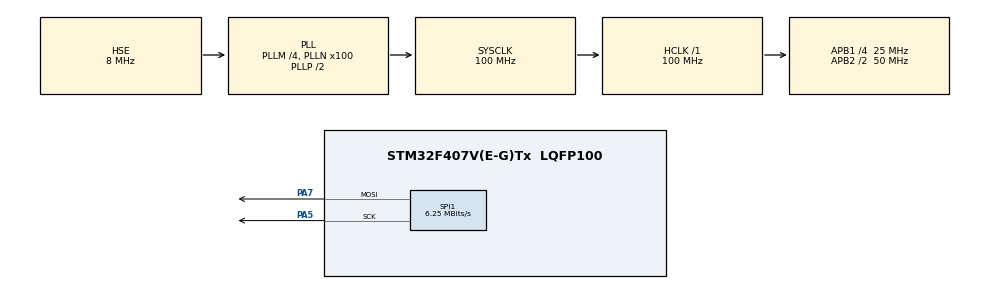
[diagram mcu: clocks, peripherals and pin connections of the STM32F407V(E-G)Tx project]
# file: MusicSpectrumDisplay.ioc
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Dma.Request0=SPI1_TX
Dma.SPI1_TX.0.Direction=DMA_MEMORY_TO_PERIPH
Dma.SPI1_TX.0.FIFOMode=DMA_FIFOMODE_DISABLE
Dma.SPI1_TX.0.Instance=DMA2_Stream3
Dma.SPI1_TX.0.MemDataAlignment=DMA_MDATAALIGN_BYTE
Dma.SPI1_TX.0.MemInc=DMA_MINC_ENABLE
Dma.SPI1_TX.0.Mode=DMA_CIRCULAR
Dma.SPI1_TX.0.PeriphDataAlignment=DMA_PDATAALIGN_BYTE
Dma.SPI1_TX.0.PeriphInc=DMA_PINC_DISABLE
Dma.SPI1_TX.0.Priority=DMA_PRIORITY_VERY_HIGH
Mcu.Family=STM32F4
Mcu.Name=STM32F407V(E-G)Tx
Mcu.Package=LQFP100
NVIC.DMA2_Stream3_IRQn=true\:0\:0\:false\:false\:true\:false
NVIC.PriorityGroup=NVIC_PRIORITYGROUP_4
PA5.Mode=TX_Only_Simplex_Unidirect_Master
PA5.Signal=SPI1_SCK
PA7.Mode=TX_Only_Simplex_Unidirect_Master
PA7.Signal=SPI1_MOSI
PH0-OSC_IN.Mode=HSE-External-Oscillator
PH0-OSC_IN.Signal=RCC_OSC_IN
PH1-OSC_OUT.Mode=HSE-External-Oscillator
PH1-OSC_OUT.Signal=RCC_OSC_OUT
ProjectManager.HeapSize=0x200
ProjectManager.StackSize=0x400
ProjectManager.TargetToolchain=SW4STM32
RCC.48MHZClocksFreq_Value=50000000
RCC.AHBFreq_Value=100000000
RCC.APB1CLKDivider=RCC_HCLK_DIV4
RCC.APB1Freq_Value=25000000
RCC.APB1TimFreq_Value=50000000
RCC.APB2CLKDivider=RCC_HCLK_DIV2
RCC.APB2Freq_Value=50000000
RCC.APB2TimFreq_Value=100000000
RCC.CortexFreq_Value=100000000
RCC.HCLKFreq_Value=100000000
RCC.HSE_VALUE=8000000
RCC.HSI_VALUE=16000000
RCC.LSE_VALUE=32768
RCC.PLLM=4
RCC.PLLN=100
RCC.PLLSourceVirtual=RCC_PLLSOURCE_HSE
RCC.SYSCLKFreq_VALUE=100000000
RCC.SYSCLKSource=RCC_SYSCLKSOURCE_PLLCLK
RCC.VCOOutputFreq_Value=200000000
SPI1.BaudRatePrescaler=SPI_BAUDRATEPRESCALER_8
SPI1.CalculateBaudRate=6.25 MBits/s
SPI1.Direction=SPI_DIRECTION_2LINES
SPI1.Mode=SPI_MODE_MASTER
SPI1.VirtualType=VM_MASTER
board=custom

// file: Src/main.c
/* USER CODE BEGIN Header */
/**
  ******************************************************************************
  * @file           : main.c
  * @brief          : Main program body
  ******************************************************************************
  ** This notice applies to any and all portions of this file
  * that are not between comment pairs USER CODE BEGIN and
  * USER CODE END. Other portions of this file, whether
  * inserted by the user or by software development tools
  * are owned by their respective copyright owners.
  *
  * COPYRIGHT(c) 2019 STMicroelectronics
  *
  * Redistribution and use in source and binary forms, with or without modification,
  * are permitted provided that the following conditions are met:
  *   1. Redistributions of source code must retain the above copyright notice,
  *      this list of conditions and the following disclaimer.
  *   2. Redistributions in binary form must reproduce the above copyright notice,
  *      this list of conditions and the following disclaimer in the documentation
  *      and/or other materials provided with the distribution.
  *   3. Neither the name of STMicroelectronics nor the names of its contributors
  *      may be used to endorse or promote products derived from this software
  *      without specific prior written permission.
  *
  * THIS SOFTWARE IS PROVIDED BY THE COPYRIGHT HOLDERS AND CONTRIBUTORS "AS IS"
  * AND ANY EXPRESS OR IMPLIED WARRANTIES, INCLUDING, BUT NOT LIMITED TO, THE
  * IMPLIED WARRANTIES OF MERCHANTABILITY AND FITNESS FOR A PARTICULAR PURPOSE ARE
  * DISCLAIMED. IN NO EVENT SHALL THE COPYRIGHT HOLDER OR CONTRIBUTORS BE LIABLE
  * FOR ANY DIRECT, INDIRECT, INCIDENTAL, SPECIAL, EXEMPLARY, OR CONSEQUENTIAL
  * DAMAGES (INCLUDING, BUT NOT LIMITED TO, PROCUREMENT OF SUBSTITUTE GOODS OR
  * SERVICES; LOSS OF USE, DATA, OR PROFITS; OR BUSINESS INTERRUPTION) HOWEVER
  * CAUSED AND ON ANY THEORY OF LIABILITY, WHETHER IN CONTRACT, STRICT LIABILITY,
  * OR TORT (INCLUDING NEGLIGENCE OR OTHERWISE) ARISING IN ANY WAY OUT OF THE USE
  * OF THIS SOFTWARE, EVEN IF ADVISED OF THE POSSIBILITY OF SUCH DAMAGE.
  *
  ******************************************************************************
  */
/* USER CODE END Header */

#include "main.h"

/* USER CODE BEGIN Includes */
#include "stm32f4xx_hal.h"
#include <stdlib.h>
#include <math.h>
#include "ws2812b.h"
#include "ws2812b_fx.h"
#include "msd_effect.h"
/* USER CODE END Includes */

SPI_HandleTypeDef hspi1;
DMA_HandleTypeDef hdma_spi1_tx;

/* USER CODE BEGIN PV */
uint16_t speedALL = 10000;
volatile int tablica_max_mocy[5]={6,8,12,8,6};
volatile int tablica_mocy[5]={1,1,1,1,1};
/* USER CODE END PV */

void SystemClock_Config(void);
static void MX_GPIO_Init(void);
static void MX_DMA_Init(void);
static void MX_SPI1_Init(void);

int main(void)
{

  /* MCU Configuration--------------------------------------------------------*/

  /* Reset of all peripherals, Initializes the Flash interface and the Systick. */
  HAL_Init();

  /* Configure the system clock */
  SystemClock_Config();

  /* Initialize all configured peripherals */
  MX_GPIO_Init();
  MX_DMA_Init();
  MX_SPI1_Init();
  /* USER CODE BEGIN 2 */
  WS2812B_Init(&hspi1);

  WS2812BFX_Init(5);	// Start 5 segments
  SetSegments();

  WS2812BFX_SetColorRGB(0, 0,62,64);	// Set color 0
  WS2812BFX_SetColorRGB(1, 0,0,0);	// Set color 1
  WS2812BFX_SetColorRGB(2, 0,0,0);		// Set color 2

  SetSegmentParams(0, speedALL, FX_MODE_SPECTRUM);
  SetSegmentParams(1, speedALL, FX_MODE_SPECTRUM);
  SetSegmentParams(2, speedALL, FX_MODE_SPECTRUM);
  SetSegmentParams(3, speedALL, FX_MODE_SPECTRUM);
  SetSegmentParams(4, speedALL, FX_MODE_SPECTRUM);

  WS2812BFX_Start(0);	// Start segment 0
  WS2812BFX_Start(1);	// Start segment 1
  WS2812BFX_Start(2);	// Start segment 2
  WS2812BFX_Start(3);	// Start segment 3
  WS2812BFX_Start(4);	// Start segment 4

  HAL_Delay(200);
  /* USER CODE END 2 */

  /* Infinite loop */
  while (1)
  {

    /* USER CODE BEGIN 3 */
	  WS2812BFX_Callback();	// FX effects calllback
	  WS2812BFX_SysTickCallback();
  }
  /* USER CODE END 3 */
}

void SystemClock_Config(void)
{
  RCC_OscInitTypeDef RCC_OscInitStruct = {0};
  RCC_ClkInitTypeDef RCC_ClkInitStruct = {0};

  /**Configure the main internal regulator output voltage
  */
  __HAL_RCC_PWR_CLK_ENABLE();
  __HAL_PWR_VOLTAGESCALING_CONFIG(PWR_REGULATOR_VOLTAGE_SCALE1);
  /**Initializes the CPU, AHB and APB busses clocks
  */
  RCC_OscInitStruct.OscillatorType = RCC_OSCILLATORTYPE_HSE;
  RCC_OscInitStruct.HSEState = RCC_HSE_ON;
  RCC_OscInitStruct.PLL.PLLState = RCC_PLL_ON;
  RCC_OscInitStruct.PLL.PLLSource = RCC_PLLSOURCE_HSE;
  RCC_OscInitStruct.PLL.PLLM = 4;
  RCC_OscInitStruct.PLL.PLLN = 100;
  RCC_OscInitStruct.PLL.PLLP = RCC_PLLP_DIV2;
  RCC_OscInitStruct.PLL.PLLQ = 4;
  if (HAL_RCC_OscConfig(&RCC_OscInitStruct) != HAL_OK)
  {
    Error_Handler();
  }
  /**Initializes the CPU, AHB and APB busses clocks
  */
  RCC_ClkInitStruct.ClockType = RCC_CLOCKTYPE_HCLK|RCC_CLOCKTYPE_SYSCLK
                              |RCC_CLOCKTYPE_PCLK1|RCC_CLOCKTYPE_PCLK2;
  RCC_ClkInitStruct.SYSCLKSource = RCC_SYSCLKSOURCE_PLLCLK;
  RCC_ClkInitStruct.AHBCLKDivider = RCC_SYSCLK_DIV1;
  RCC_ClkInitStruct.APB1CLKDivider = RCC_HCLK_DIV4;
  RCC_ClkInitStruct.APB2CLKDivider = RCC_HCLK_DIV2;

  if (HAL_RCC_ClockConfig(&RCC_ClkInitStruct, FLASH_LATENCY_3) != HAL_OK)
  {
    Error_Handler();
  }
}

static void MX_SPI1_Init(void)
{

  /* SPI1 parameter configuration*/
  hspi1.Instance = SPI1;
  hspi1.Init.Mode = SPI_MODE_MASTER;
  hspi1.Init.Direction = SPI_DIRECTION_2LINES;
  hspi1.Init.DataSize = SPI_DATASIZE_8BIT;
  hspi1.Init.CLKPolarity = SPI_POLARITY_LOW;
  hspi1.Init.CLKPhase = SPI_PHASE_1EDGE;
  hspi1.Init.NSS = SPI_NSS_SOFT;
  hspi1.Init.BaudRatePrescaler = SPI_BAUDRATEPRESCALER_8;
  hspi1.Init.FirstBit = SPI_FIRSTBIT_MSB;
  hspi1.Init.TIMode = SPI_TIMODE_DISABLE;
  hspi1.Init.CRCCalculation = SPI_CRCCALCULATION_DISABLE;
  hspi1.Init.CRCPolynomial = 10;
  if (HAL_SPI_Init(&hspi1) != HAL_OK)
  {
    Error_Handler();
  }

}

static void MX_DMA_Init(void)
{
  /* DMA controller clock enable */
  __HAL_RCC_DMA2_CLK_ENABLE();

  /* DMA interrupt init */
  /* DMA2_Stream3_IRQn interrupt configuration */
  HAL_NVIC_SetPriority(DMA2_Stream3_IRQn, 0, 0);
  HAL_NVIC_EnableIRQ(DMA2_Stream3_IRQn);

}

static void MX_GPIO_Init(void)
{

  /* GPIO Ports Clock Enable */
  __HAL_RCC_GPIOH_CLK_ENABLE();
  __HAL_RCC_GPIOA_CLK_ENABLE();

}

/* USER CODE BEGIN 4 */
void HAL_SYSTICK_Callback(void)
{
	WS2812BFX_SysTickCallback();
}
/* USER CODE END 4 */

void Error_Handler(void)
{
}

/************************ (C) COPYRIGHT STMicroelectronics *****END OF FILE****/
